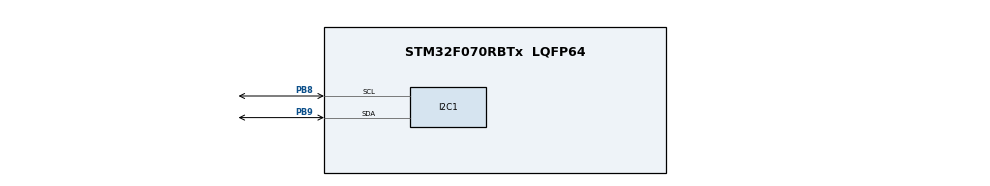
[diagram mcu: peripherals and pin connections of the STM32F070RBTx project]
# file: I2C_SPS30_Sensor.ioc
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Mcu.Family=STM32F0
Mcu.Name=STM32F070RBTx
Mcu.Package=LQFP64
PB8.Mode=I2C
PB8.Signal=I2C1_SCL
PB9.Mode=I2C
PB9.Signal=I2C1_SDA
ProjectManager.HeapSize=0x200
ProjectManager.StackSize=0x400
ProjectManager.TargetToolchain=STM32CubeIDE
board=custom

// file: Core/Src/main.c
/* USER CODE BEGIN Header */
/**
 ******************************************************************************
 * @file           : main.c
 * @brief          : Main program body
 ******************************************************************************
 * @attention
 *
 * Copyright (c) 2022 STMicroelectronics.
 * All rights reserved.
 *
 * This software is licensed under terms that can be found in the LICENSE file
 * in the root directory of this software component.
 * If no LICENSE file comes with this software, it is provided AS-IS.
 *
 ******************************************************************************
 */
/* USER CODE END Header */
#include "main.h"
#include "i2c.h"
#include "gpio.h"

/* USER CODE BEGIN Includes */
#include "sps30.h"
/* USER CODE END Includes */

/* USER CODE BEGIN PV */
extern particleData pd;
extern uint8_t dataReadyFlag[3];
/* USER CODE END PV */

void SystemClock_Config(void);

/* USER CODE BEGIN 0 */

uint16_t massConcentration1_0, massConcentration2_5, massConcentration4_0, massConcentration10, numberConcentration0_5, numberConcentration1_0, numberConcentration2_5, numberConcentration4_0, numberConcentration10, particleSize;

/* USER CODE END 0 */

int main(void)
{

  /* MCU Configuration--------------------------------------------------------*/

  /* Reset of all peripherals, Initializes the Flash interface and the Systick. */
  HAL_Init();

  /* Configure the system clock */
  SystemClock_Config();

  /* Initialize all configured peripherals */
  MX_GPIO_Init();
  MX_I2C1_Init();
  /* USER CODE BEGIN 2 */
	HAL_Delay(50);
	startMeasurement();
	HAL_Delay(2000);
	readDataReadyFlag();
	while (!(dataReadyFlag[1])) {
		readDataReadyFlag();
	}
  /* USER CODE END 2 */

  /* Infinite loop */
	while (1) {

    /* USER CODE BEGIN 3 */
		readMeasuredValues();
		massConcentration1_0 = pd.massConcentration1_0;
		massConcentration2_5 = pd.massConcentration2_5;
		massConcentration4_0 = pd.massConcentration4_0;
		massConcentration10 = pd.massConcentration10;
		numberConcentration0_5 = pd.numberConcentration0_5;
		numberConcentration1_0 = pd.numberConcentration1_0;
		numberConcentration2_5 = pd.numberConcentration2_5;
		numberConcentration4_0 = pd.numberConcentration4_0;
		numberConcentration10 = pd.numberConcentration10;
		particleSize = pd.particleSize;
		HAL_Delay(500);
	}
  /* USER CODE END 3 */
}

void SystemClock_Config(void)
{
  RCC_OscInitTypeDef RCC_OscInitStruct = {0};
  RCC_ClkInitTypeDef RCC_ClkInitStruct = {0};
  RCC_PeriphCLKInitTypeDef PeriphClkInit = {0};

  /** Initializes the RCC Oscillators according to the specified parameters
  * in the RCC_OscInitTypeDef structure.
  */
  RCC_OscInitStruct.OscillatorType = RCC_OSCILLATORTYPE_HSI;
  RCC_OscInitStruct.HSIState = RCC_HSI_ON;
  RCC_OscInitStruct.HSICalibrationValue = RCC_HSICALIBRATION_DEFAULT;
  RCC_OscInitStruct.PLL.PLLState = RCC_PLL_NONE;
  if (HAL_RCC_OscConfig(&RCC_OscInitStruct) != HAL_OK)
  {
    Error_Handler();
  }

  /** Initializes the CPU, AHB and APB buses clocks
  */
  RCC_ClkInitStruct.ClockType = RCC_CLOCKTYPE_HCLK|RCC_CLOCKTYPE_SYSCLK
                              |RCC_CLOCKTYPE_PCLK1;
  RCC_ClkInitStruct.SYSCLKSource = RCC_SYSCLKSOURCE_HSI;
  RCC_ClkInitStruct.AHBCLKDivider = RCC_SYSCLK_DIV1;
  RCC_ClkInitStruct.APB1CLKDivider = RCC_HCLK_DIV1;

  if (HAL_RCC_ClockConfig(&RCC_ClkInitStruct, FLASH_LATENCY_0) != HAL_OK)
  {
    Error_Handler();
  }
  PeriphClkInit.PeriphClockSelection = RCC_PERIPHCLK_I2C1;
  PeriphClkInit.I2c1ClockSelection = RCC_I2C1CLKSOURCE_HSI;
  if (HAL_RCCEx_PeriphCLKConfig(&PeriphClkInit) != HAL_OK)
  {
    Error_Handler();
  }
}

void Error_Handler(void)
{
	__disable_irq();
	while (1) {
	}
}
